# ATSAMA5D27 register map
Vendor: Microchip Technology Inc.; File version: 1.0
CPU: CA5 r0p1, little endian, no MPU, no FPU, 4 interrupt priority bits
Address unit: 32 bits
Registers are 32-bit, read-write, reset 0x0 unless marked. A register's access mark holds for its fields unless they carry their own. Offsets are from the block's base; [hi:lo] are bit positions; {n}, {i} and the like mark numbered series; 'fields as' and 'values as' point back to an identical list.

## L2CC — L2 Cache Controller
Base 0x00A00000
0x00 IDR ro — Cache ID Register
  [31:0] ID rw — Cache Controller ID
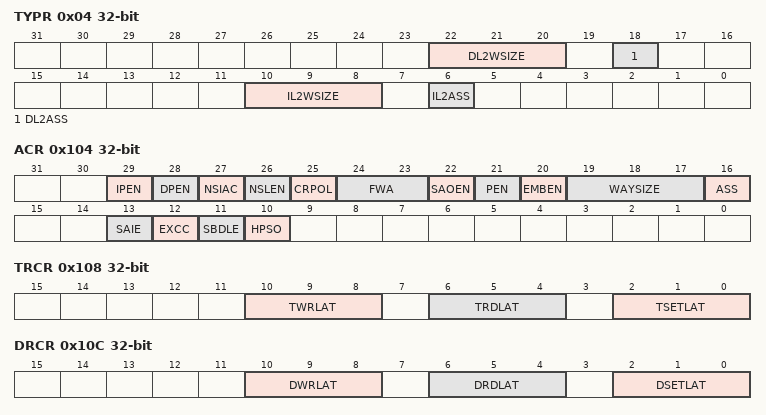
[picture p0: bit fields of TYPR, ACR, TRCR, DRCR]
0x04 TYPR ro — Cache Type Register
  [22:20] DL2WSIZE rw — Data L2 Cache Way Size
  [18] DL2ASS rw — Data L2 Cache Associativity
  [10:8] IL2WSIZE rw — Instruction L2 Cache Way Size
  [6] IL2ASS rw — Instruction L2 Cache Associativity
0x100 CR — Control Register
  [0] L2CEN — L2 Cache Enable
0x104 ACR — Auxiliary Control Register
  [29] IPEN — Instruction Prefetch Enable
  [28] DPEN — Data Prefetch Enable
  [27] NSIAC — Non-Secure Interrupt Access Control
  [26] NSLEN — Non-Secure Lockdown Enable
  [25] CRPOL — Cache Replacement Policy
  [24:23] FWA — Force Write Allocate
  [22] SAOEN — Shared Attribute Override Enable
  [21] PEN — Parity Enable
  [20] EMBEN — Event Monitor Bus Enable
  [19:17] WAYSIZE
    1=_16KB_WAY (16-Kbyte way set associative)
  [16] ASS — Associativity
  [13] SAIE — Shared Attribute Invalidate Enable
  [12] EXCC — Exclusive Cache Configuration
  [11] SBDLE — Store Buffer Device Limitation Enable
  [10] HPSO — High Priority for SO and Dev Reads Enable
0x108 TRCR — Tag RAM Control Register
  [10:8] TWRLAT — Write Access Latency
  [6:4] TRDLAT — Read Access Latency
  [2:0] TSETLAT — Setup Latency
0x10C DRCR — Data RAM Control Register
  [10:8] DWRLAT — Write Access Latency
  [6:4] DRDLAT — Read Access Latency
  [2:0] DSETLAT — Setup Latency
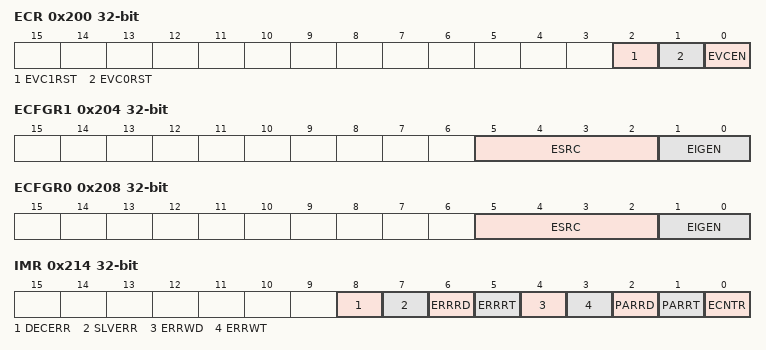
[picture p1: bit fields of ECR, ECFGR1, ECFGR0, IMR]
0x200 ECR — Event Counter Control Register
  [2] EVC1RST — Event Counter 1 Reset
  [1] EVC0RST — Event Counter 0 Reset
  [0] EVCEN — Event Counter Enable
0x204 ECFGR1 — Event Counter 1 Configuration Register
  [5:2] ESRC — Event Counter Source
    0=CNT_DIS (Counter Disabled); 1=SRC_CO (Source is CO); 2=SRC_DRHIT (Source is DRHIT); 3=SRC_DRREQ (Source is DRREQ); 4=SRC_DWHIT (Source is DWHIT); 5=SRC_DWREQ (Source is DWREQ); 6=SRC_DWTREQ (Source is DWTREQ); 7=SRC_IRHIT (Source is IRHIT); 8=SRC_IRREQ (Source is IRREQ); 9=SRC_WA (Source is WA); 10=SRC_IPFALLOC (Source is IPFALLOC); 11=SRC_EPFHIT (Source is EPFHIT); 12=SRC_EPFALLOC (Source is EPFALLOC); 13=SRC_SRRCVD (Source is SRRCVD); 14=SRC_SRCONF (Source is SRCONF); 15=SRC_EPFRCVD (Source is EPFRCVD)
  [1:0] EIGEN — Event Counter Interrupt Generation
    0=INT_DIS (Disables (default)); 1=INT_EN_INCR (Enables with Increment condition); 2=INT_EN_OVER (Enables with Overflow condition); 3=INT_GEN_DIS (Disables Interrupt generation)
0x208 ECFGR0 — Event Counter 0 Configuration Register
  fields as ECFGR1
0x20C EVR1 — Event Counter 1 Value Register
  [31:0] VALUE — Event Counter Value
0x210 EVR0 — Event Counter 0 Value Register
  [31:0] VALUE — Event Counter Value
0x214 IMR — Interrupt Mask Register
  [8] DECERR — DECERR from L3 Memory
  [7] SLVERR — SLVERR from L3 Memory
  [6] ERRRD — Error on L2 Data RAM, Read
  [5] ERRRT — Error on L2 Tag RAM, Read
  [4] ERRWD — Error on L2 Data RAM, Write
  [3] ERRWT — Error on L2 Tag RAM, Write
  [2] PARRD — Parity Error on L2 Data RAM, Read
  [1] PARRT — Parity Error on L2 Tag RAM, Read
  [0] ECNTR — Event Counter 1/0 Overflow Increment
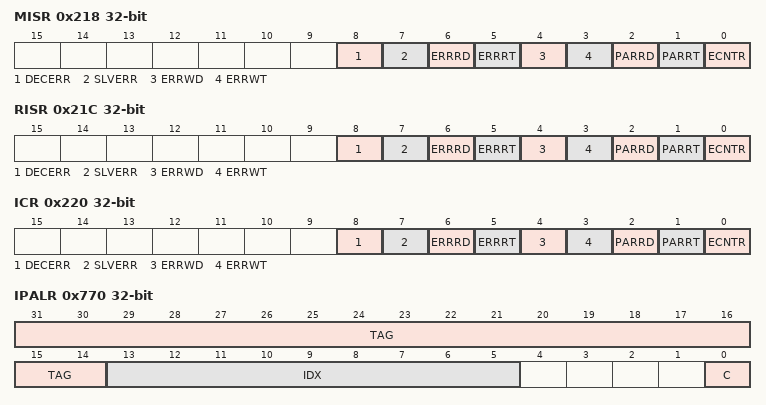
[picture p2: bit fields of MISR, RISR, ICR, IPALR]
0x218 MISR ro — Masked Interrupt Status Register
  [8] DECERR rw — DECERR from L3 memory
  [7] SLVERR rw — SLVERR from L3 memory
  [6] ERRRD rw — Error on L2 Data RAM, Read
  [5] ERRRT rw — Error on L2 Tag RAM, Read
  [4] ERRWD rw — Error on L2 Data RAM, Write
  [3] ERRWT rw — Error on L2 Tag RAM, Write
  [2] PARRD rw — Parity Error on L2 Data RAM, Read
  [1] PARRT rw — Parity Error on L2 Tag RAM, Read
  [0] ECNTR rw — Event Counter 1/0 Overflow Increment
0x21C RISR ro — Raw Interrupt Status Register
  fields as MISR
0x220 ICR — Interrupt Clear Register
  [8] DECERR — DECERR from L3 memory
  [7] SLVERR — SLVERR from L3 memory
  [6] ERRRD — Error on L2 Data RAM, Read
  [5] ERRRT — Error on L2 Tag RAM, Read
  [4] ERRWD — Error on L2 Data RAM, Write
  [3] ERRWT — Error on L2 Tag RAM, Write
  [2] PARRD — Parity Error on L2 Data RAM, Read
  [1] PARRT — Parity Error on L2 Tag RAM, Read
  [0] ECNTR — Event Counter 1/0 Overflow Increment
0x730 CSR — Cache Synchronization Register
  [0] C — Cache Synchronization Status
0x770 IPALR — Invalidate Physical Address Line Register
  [31:14] TAG — Tag Number
  [13:5] IDX — Index Number
  [0] C — Cache Synchronization Status
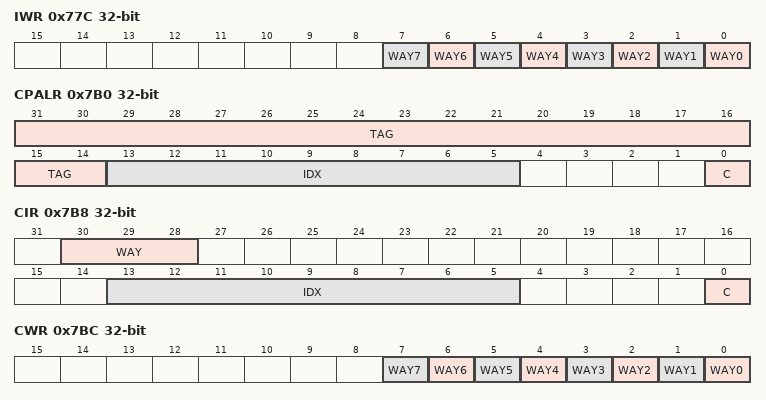
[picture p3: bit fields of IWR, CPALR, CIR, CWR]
0x77C IWR — Invalidate Way Register
  [n] WAY{n} (n=0..7) — Invalidate Way Number {n}
0x7B0 CPALR — Clean Physical Address Line Register
  [31:14] TAG — Tag number
  [13:5] IDX — Index number
  [0] C — Cache Synchronization Status
0x7B8 CIR — Clean Index Register
  [30:28] WAY — Way number
  [13:5] IDX — Index number
  [0] C — Cache Synchronization Status
0x7BC CWR — Clean Way Register
  [n] WAY{n} (n=0..7) — Clean Way Number {n}
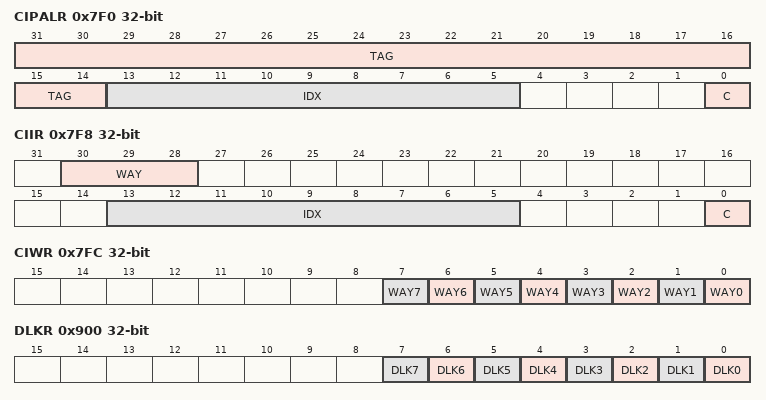
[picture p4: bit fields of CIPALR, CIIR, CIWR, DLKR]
0x7F0 CIPALR — Clean Invalidate Physical Address Line Register
  fields as IPALR
0x7F8 CIIR — Clean Invalidate Index Register
  [30:28] WAY — Way Number
  [13:5] IDX — Index Number
  [0] C — Cache Synchronization Status
0x7FC CIWR — Clean Invalidate Way Register
  [n] WAY{n} (n=0..7) — Clean Invalidate Way Number {n}
0x900 DLKR — Data Lockdown Register
  [n] DLK{n} (n=0..7) — Data Lockdown in Way Number {n}
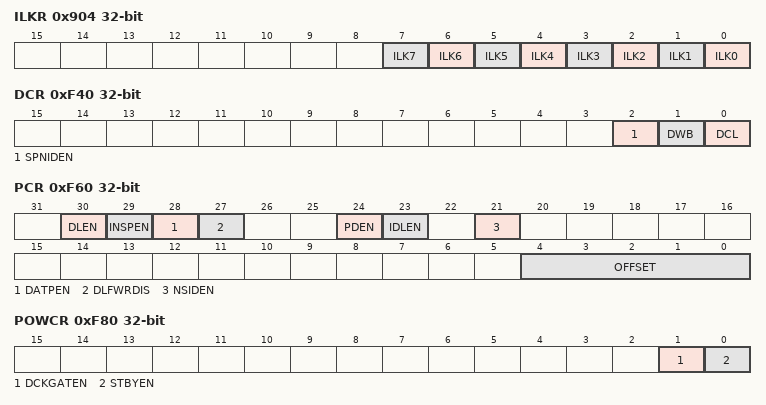
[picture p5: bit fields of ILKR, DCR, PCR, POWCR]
0x904 ILKR — Instruction Lockdown Register
  [n] ILK{n} (n=0..7) — Instruction Lockdown in Way Number {n}
0xF40 DCR — Debug Control Register
  [2] SPNIDEN — SPNIDEN Value
  [1] DWB — Disable Write-back, Force Write-through
  [0] DCL — Disable Cache Linefill
0xF60 PCR — Prefetch Control Register
  [30] DLEN — Double Linefill Enable
  [29] INSPEN — Instruction Prefetch Enable
  [28] DATPEN — Data Prefetch Enable
  [27] DLFWRDIS — Double Linefill on WRAP Read Disable
  [24] PDEN — Prefetch Drop Enable
  [23] IDLEN — INCR Double Linefill Enable
  [21] NSIDEN — Not Same ID on Exclusive Sequence Enable
  [4:0] OFFSET — Prefetch Offset
0xF80 POWCR — Power Control Register
  [1] DCKGATEN — Dynamic Clock Gating Enable
  [0] STBYEN — Standby Mode Enable
